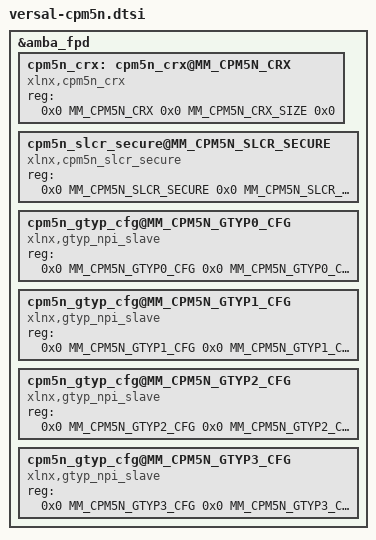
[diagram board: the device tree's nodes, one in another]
/*
 * Versal CPM5N devices
 *
 * Copyright (c) 2021, Xilinx Inc
 * All rights reserved.
 *
 * SPDX-License-Identifier: BSD-3-Clause
 */

#ifndef MM_CPM
# define MM_CPM MM_INTCPM5N_CONFIG
# define MM_CPM_SIZE (MM_CPM5N_PCSR + MM_CPM5N_PCSR_SIZE - MM_INTCPM5N_CONFIG)
#endif

&amba_fpd {
	cpm5n_crx: cpm5n_crx@MM_CPM5N_CRX {
		compatible = "xlnx,cpm5n_crx";
		reg = <0x0 MM_CPM5N_CRX 0x0 MM_CPM5N_CRX_SIZE 0x0>;
	};

	cpm5n_slcr_secure@MM_CPM5N_SLCR_SECURE {
		compatible = "xlnx,cpm5n_slcr_secure";
		reg = <0x0 MM_CPM5N_SLCR_SECURE 0x0 MM_CPM5N_SLCR_SECURE_SIZE 0x0>;
	};

	cpm5n_gtyp_cfg@MM_CPM5N_GTYP0_CFG {
		compatible = "xlnx,gtyp_npi_slave";
		reg = <0x0 MM_CPM5N_GTYP0_CFG 0x0 MM_CPM5N_GTYP0_CFG_SIZE 0x0>;
	};

	cpm5n_gtyp_cfg@MM_CPM5N_GTYP1_CFG {
		compatible = "xlnx,gtyp_npi_slave";
		reg = <0x0 MM_CPM5N_GTYP1_CFG 0x0 MM_CPM5N_GTYP1_CFG_SIZE 0x0>;
	};

	cpm5n_gtyp_cfg@MM_CPM5N_GTYP2_CFG {
		compatible = "xlnx,gtyp_npi_slave";
		reg = <0x0 MM_CPM5N_GTYP2_CFG 0x0 MM_CPM5N_GTYP2_CFG_SIZE 0x0>;
	};

	cpm5n_gtyp_cfg@MM_CPM5N_GTYP3_CFG {
		compatible = "xlnx,gtyp_npi_slave";
		reg = <0x0 MM_CPM5N_GTYP3_CFG 0x0 MM_CPM5N_GTYP3_CFG_SIZE 0x0>;
	};
};
